# SN32F290 register map
Vendor: SONIX; File version: 2026.10.03
CPU: CM0 r0p0, little endian, no MPU, no FPU, 2 interrupt priority bits
Registers are 32-bit, read-write, reset 0x0 unless marked. A register's access mark holds for its fields unless they carry their own. Offsets are from the block's base; [hi:lo] are bit positions; {n}, {i} and the like mark numbered series.

## SN_CRC — Cyclic Redundancy Check
Base 0x40038000
0x00 CTRL (reset mask 0x1F) — Offset:0x0 CRC Control Register
  [8:4] BUSY ro — CRC calculation busy flag
    0=Idle_Finish (CRC calculation idle/finished); 1=CRC calculation is in process
  [6:3] URCRCEN — CRC calculation for the User ROM enable bit
    0=Stop/Finish CRC calculation; 1=Enable_145 (Start CRC calculation for the User ROM)
  [4:2] RESET — CRC Reset bit
    0=No_58 (No effect); 1=Reset_V (Reset CRC circuit)
  [1:0] CRC — CRC Polynomial
    0=CRC_16_CCITT (CRC-16-CCITT Polynomial); 1=CRC-16 Polynomial; 2=CRC-32 Polynomial
0x04 DATA — Offset:0x4 CRC Data Register
  [31:0] DATA — CRC Data

## SN_FLASH — FLASH Memory Control Registers
Base 0x40062000
0x00 LPCTRL (reset mask 0xFFFF003B) — Offset:0x00 Flash Low Power Control Register
  [47:16] FMCKEY wo — FMC verify key
  [5:0] LPMODE — Flash Low Power mode selection bit
    0=V_0x0 (HCLK is less than or equal to 24MHz); 25=V_0x19 (HCLK is more than 24MHz, and less than or equal to 48MHz); 57=V_0x39 (HCLK is more than 48MHz)
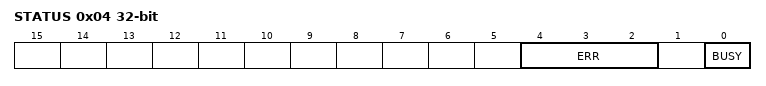
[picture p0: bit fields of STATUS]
0x04 STATUS (reset mask 0x5) — Offset:0x04 Flash Status Register
  [4:2] ERR — Erase/Error flag
    0=No_error; 1=Error_2 (The address is illegal or over page boundary)
  [0] BUSY ro — Busy flag
    0=Idle_6 (FMC is idle); 1=Flash operation is in process
0x08 CTRL (reset mask 0xC7) — Offset:0x08 Flash Control Register
  [14:7] CHK — Checksum calculation chosen
    0=Disable_434 (Disable checksum calcuation); 1=Enable_145 (Trigger checksum calculation)
  [12:6] START — Start erase/program operation
    0=Stop/finish operation; 1=Start erase/program operation
  [4:2] MER — Mass erase mode chosen bit
    0=V_0_164 (Disable masse erase mode); 1=V_1_374 (Enable mass erase mode)
  [2:1] PER — Page erase mode chosen bit
    0=V_0_164 (Disable page erase mode); 1=V_1_374 (Enable page erase mode)
  [0] PG — Flash program mode chosen bit
    0=V_0_164 (Disable Flash program mode); 1=V_1_374 (Enable Flash program mode)
0x0C DATA — Offset:0x0C Flash Data Register
0x10 ADDR — Offset:0x10 Flash Address Register
0x14 CHKSUM ro — Offset:0x14 Flash Checksum Register
  [47:16] BootROM — Checksum of Boot ROM
  [15:0] UserROM — Checksum of User ROM
0x18 CHKSUM1 ro — Offset:0x18 Flash Checksum Register 1
  [47:16] UserROM2 — Checksum of User ROM 2
  [15:0] UserROM1 — Checksum of User ROM 1
0x1C CHKSUM2 ro — Offset:0x1C Flash Checksum Register 2
  [47:16] UserROM4 — Checksum of User ROM 4
  [15:0] UserROM3 — Checksum of User ROM 3

## SN_I2C0 — I2C0
Base 0x40018000
Same registers: SN_I2C1 0x4005A000
0x00 CTRL (reset mask 0x1B6) — Offset:0x00 I2Cn Control Register
  [16:8] I2CEN — I2Cn interface enable
    0=Disable_434 (Disable I2C); 1=Enable_145 (Enable I2C)
  [14:7] I2CMODE
    0=Standard_Fast_mode_2
  [10:5] STA — START assert flag
    0=No_action_4 (No START condition or Repeated START condition will be generated); 1=Assert_10 (Enter master mode and transmit a START or Repeated START condition)
  [8:4] STO — STOP assert flag
    0=Idle_6 (STOP condition idle); 1=Assert_10 (Transmit a STOP condition in master mode, or recover from an error condition in slave mode)
  [4:2] ACK — ACK assert flag
    0=No_58 (Master: No action/Slave: Assert NACK after receiving); 1=Assert_10 (Assert ACK during the acknowledge clock pulse on SCLn)
  [2:1] NACK — NACK assert flag
    0=No_action_4; 1=Assert_10 (Assert NACK during the acknowledge clock pulse on SCLn)
0x04 STAT (reset mask 0x83FF) — Offset:0x04 I2Cn Status Register
  [30:15] I2CIF — I2C interrupt flag
    0=V_0_164 (I2C status doesn't change); 1=V_1_374 (I2C status changes)
  [18:9] TIMEOUT ro — Time-out status
    0=V_0_164 (No timeout); 1=V_1_374 (Timeout)
  [16:8] LOST_ARB ro — Lost arbitration status
    0=V_0_164 (Not lost arbitration); 1=V_1_374 (Lost arbitration)
  [14:7] SLV_TX_HIT ro — Slave TX address hit flag
    0=V_0_164 (No matched slave address); 1=V_1_374 (Slave address hit, and is called for TX)
  [12:6] SLV_RX_HIT ro — Slave RX address hit flag
    0=V_0_164 (No matched slave address); 1=V_1_374 (Slave address hit, and is called for RX)
  [10:5] MST ro — I2C master/slave status
    0=Slave_6 (Act as Slave); 1=Master_3 (Act as Master)
  [8:4] START_DN ro — START done status
    0=No_58 (No START condition); 1=Assert_10 (Transmit or receive a START condition)
  [6:3] STOP_DN ro — STOP done status
    0=No_58 (No STOP condition); 1=Done_3 (Transmit or receive a STOP condition)
  [4:2] NACK_STAT ro — NACK done status
    0=No_58 (No NACK received); 1=Done_3 (Receive a NACK)
  [2:1] ACK_STAT ro — ACK done status
    0=No_58 (No ACK received); 1=Done_3 (Receive an ACK)
  [0] RX_DN ro — RX done status
    0=Not_done_2 (No RX with ACK/NACK transfer); 1=Done_3 (8-bit RX with ACK/NACK transfer)
0x08 TXDATA — Offset:0x08 I2Cn TX Data Register
  [7:0] Data — TX Data
0x0C RXDATA ro — Offset:0x0C I2Cn RX Data Register
  [7:0] Data — RX Data received when RX_DN=1
0x10 SLVADDR0 (reset mask 0xC00003FF) — Offset:0x10 I2Cn Slave Address 0 Register
  [62:31] ADD_MODE — Slave address mode
    0=V_0_164 (7-bit slave address mode); 1=V_1_374 (10-bit slave address mode)
  [60:30] GCEN — General call address enable
    0=Disable_434 (Disable general call address); 1=Enable_145 (Enable general call address (0x0))
  [9:0] ADDR — I2Cn slave address 0
{0x10+4i} SLVADDR{i} (i=1..3) — Offset:{0x10+4i} I2Cn Slave Address {i} Register
  [9:0] ADDR — I2Cn slave address {i}
0x20 SCLHT reset 0x4 — Offset:0x20 I2Cn SCL High Time Register
  [7:0] SCLH — SCLn High period time=(SCLHT+1)*I2Cn_PCLK cycle
0x24 SCLLT reset 0x4 — Offset:0x24 I2Cn SCL Low Time Register
  [7:0] SCLL — SCLn Low period time=(SCLLT+1)*I2Cn_PCLK cycle
0x2C TOCTRL — Offset:0x2C I2Cn Timeout Control Register
  [15:0] TO — Timeout period time = TO*32*I2Cn_PCLK cycle

## SN_OPA — OP Amplifier
Base 0x4002A000
0x00 CTRL (reset mask 0x1919) — Offset:0x0 OPA Control Register
  [24:12] OP1NS — OP-Amp 1 Negatiove input selection bit
    0=VOPAIREF_4 (OP1N pin is GPIO mode.); 1=OP1N (OP1N is OPA1 negative input pin, and isolate GPIO function)
  [22:11] OP1PS — OP-Amp 1 Positive input selection bit
    0=VOPAIREF_4 (OP1P pin is GPIO mode.); 1=OP0P_2 (OP1P is OPA1 positive input pin, and isolate GPIO function)
  [16:8] OP1EN — OP-Amp 1 enable bit
    0=Disable_434 (Disable OPA1); 1=Enable_145 (Enable OPA1)
  [8:4] OP0NS — OP-Amp 0 Negatiove input selection bit
    0=VOPAIREF_4 (OP0N pin is GPIO mode.); 1=OP0N (OP0N is OPA0 negative input pin, and isolate GPIO function)
  [6:3] OP0PS — OP-Amp 0 Positive input selection bit
    0=VOPAIREF_4 (OP0P pin is GPIO mode.); 1=OP0P_2 (OP0P is OPA0 positive input pin, and isolate GPIO function)
  [0] OP0EN — OP-Amp 0 enable bit
    0=Disable_434 (Disable OPA0); 1=Enable_145 (Enable OPA0)

## SN_PMU — Power Management Unit
Base 0x40032000
0x40 CTRL — Offset:0x40 PMU Control Register
  [2:0] MODE — Low Power mode selection
    0=Disable_434; 2=Deep_sleep_mode (WFI instruction will make MCU enter Deep-sleep mode); 4=Sleep_mode (WFI instruction will make MCU enter Sleep mode)

## SN_RTC — Real-time Clock
Base 0x40012000
0x00 CTRL — Offset:0x00 RTC Control Register
  [0] RTCEN — RTC enable
    0=Disable_434 (Disable RTC); 1=Enable_145 (Enable RTC)
0x04 CLKS — Offset:0x04 RTC Clock Source Register
  [0] CLKSEL — RTC clock source
    0=ILRC_2 (RTC clock source=ILRC); 1=ELS_XTAL_2 (RTC clock source=ELS XTAL)
0x08 IE — Offset:0x08 RTC Interrupt Enable Register
  [0] SECIE — Second interrupt enable
    0=Disable_434 (Disable second interrupt); 1=Enable_145 (Enable second interrupt)
0x0C RIS ro — Offset:0x0C RTC Raw Interrupt Status Register
  [0] SECIF — Second interrupt flag
    0=No_58 (No second interrupt); 1=Met_12 (Second interrupt is triggered when SECIE=1)
0x10 IC wo — Offset:0x10 RTC Interrupt Clear Register
  [0] SECIC — Second interrupt flag clear
    0=No_effect_200; 1=Clear_V_150 (Clear second interrupt flag)
0x14 SECCNTV reset 0x8000 (reset mask 0xFFFFF) — Offset:0x14 RTC Second Counter Reload Value Register
0x18 SECCNT ro — Offset:0x18 RTC Second Counter Register

## SN_UC — UC Registers
Base 0x1FFF2450
0x00 L4BYTE ro — Offset:0x00 UC Low 4 Byte Register
0x08 H4BYTE ro — Offset:0x08 UC High 4 Byte Register

## SN_WDT — Watchdog Timer
Base 0x40010000
0x00 CFG (reset mask 0xFFFF0007) — Offset:0x00 WDT Configuration Register
  [47:16] WDKEY wo — WDT register key
  [4:2] WDTINT — WDT interrupt flag
    0=No_58 (No WDT time-out); 1=WDT_time_out (WDT interrupt is triggered if WDTIE=1)
  [2:1] WDTIE — WDT interrupt enable
    0=Disable_434 (WDT reset when WDT time-out); 1=Enable_145 (Enable WDT interrupt)
  [0] WDTEN — WDT enable
    0=Disable_434 (Disable WDT); 1=Enable_145 (Enable WDT)
0x08 TC reset 0xFF (reset mask 0xFFFF00FF) — Offset:0x08 WDT Timer Constant Register
  [47:16] WDKEY wo — WDT register key
  [7:0] TC — Watchdog timer constant reload value
0x0C FEED wo — Offset:0x0C WDT Feed Register
  [47:16] WDKEY — WDT register key
  [15:0] FV — Watchdog feed value
